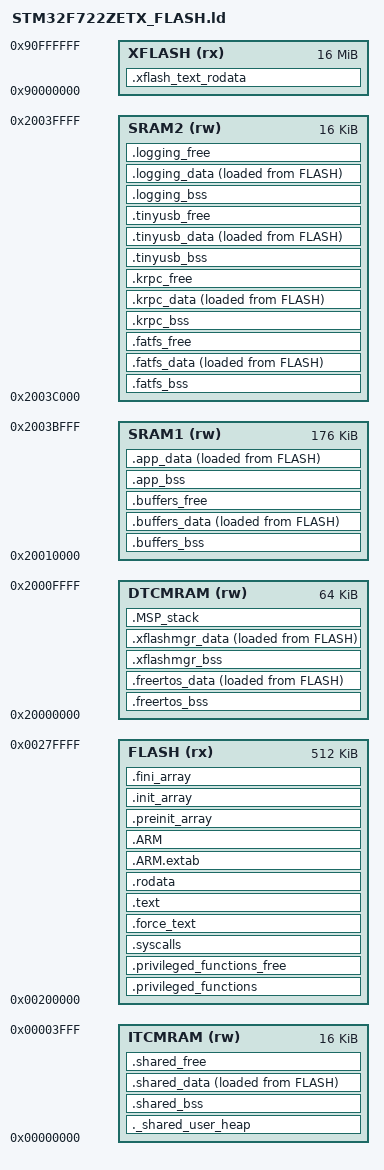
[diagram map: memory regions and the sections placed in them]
/*
******************************************************************************
**
** @file        : LinkerScript.ld
**
** @author      : Auto-generated by STM32CubeIDE
**
** @brief       : Linker script for STM32F722ZETx Device from STM32F7 series
**                      512KBytes FLASH
**                      256KBytes RAM
**
**                Set heap size, stack size and stack location according
**                to application requirements.
**
**                Set memory bank area and size if external memory is used
**
**  Target      : STMicroelectronics STM32
**
**  Distribution: The file is distributed as is, without any warranty
**                of any kind.
**
******************************************************************************
** @attention
**
** Copyright (c) 2023 STMicroelectronics.
** All rights reserved.
**
** This software is licensed under terms that can be found in the LICENSE file
** in the root directory of this software component.
** If no LICENSE file comes with this software, it is provided AS-IS.
**
******************************************************************************
*/

/* Entry Point */
ENTRY(Reset_Handler)

_Min_Heap_Size = 0x1fc; /* required amount of heap */
_Min_Stack_Size = 0x400; /* required amount of stack */

/* Memories definition */
MEMORY
{
	ITCMRAM (rw) : ORIGIN = 0x00000000, LENGTH = 16K
	DTCMRAM (rw) : ORIGIN = 0x20000000, LENGTH = 64K
	SRAM1 (rw) : ORIGIN = 0x20010000, LENGTH = 176K
	SRAM2 (rw) : ORIGIN = 0x2003C000, LENGTH = 16K
	FLASH (rx) : ORIGIN = 0x00200000, LENGTH = 512K
	XFLASH (rx) : ORIGIN = 0x90000000, LENGTH = 16M
}

INCLUDE ../glue/_regions.ld

null_ptr = 0;

/* -------------------------------------------------------------------------- */

/* Sections */
SECTIONS
{
    /* The startup code and FreeRTOS kernel code are placed into privileged
     * flash. */
    .privileged_functions :
    {
        . = ALIGN(4);
        _privileged_functions_text_run_addr = .;
        __FLASH_segment_start__ = .;
        __FLASH_segment_end__ = __FLASH_segment_start__ + LENGTH( FLASH );
        __privileged_functions_start__ = __FLASH_segment_start__;
        
        KEEP(*(.isr_vector)) /* Startup code */
        . = ALIGN(4);
        *(privileged_functions)
        
        . = ALIGN(4);
        _privileged_functions_text_end = .;
    } >FLASH
    
    .privileged_functions_free :
    {
        FILL(0xADDE);
        /* Ensure that un-privileged code is placed after the region reserved
         * for privileged kernel code. */
        /* Note that dot (.) actually refers to the byte offset from the start
         * of the current section (.privileged_functions in this case). As a
         * result, setting dot (.) to a value sets the size of the section. */
        . = __privileged_functions_region_size__ - (_privileged_functions_text_end - _privileged_functions_text_run_addr);
        __privileged_functions_end__ = .;
    } >FLASH
    
    .syscalls :
    {
	    /* Place the FreeRTOS System Calls first in the unprivileged region. */
	    . = ALIGN(4);
	    __syscalls_flash_start__ = .;
	    *(freertos_system_calls)
	    __syscalls_flash_end__ = .;
	    . = ALIGN(4);
    } > FLASH
    
	.force_text :
	{
		. = ALIGN(4);
		
		*(.force_text)
		*(.text.*_IRQHandler)
		./Drivers/*qspi.o(.text* .rodata*) /* */
		./Drivers/*gpio.o(.text* .rodata*) /* */
		
		. = ALIGN(4);
	} > FLASH
	
	.xflash_text_rodata :
	{
		/* Place the FreeRTOS System Calls first in the unprivileged region. */
		. = ALIGN(4);
        __XFLASH_segment_start__ = .;
        __XFLASH_segment_end__ = __XFLASH_segment_start__ + LENGTH( XFLASH );
		*(.xflash_text* .xflash_rodata*)
		./App/*.o(.text* .rodata*) /* */
		./Core/Src/main.o(.text* .rodata*)
		./Core/Src/stm32f7xx_hal_msp.o(.text* .rodata*)
		./Drivers/*.o(.text* .rodata*) /* */
		./lib/Fusion/*.o(.text* .rodata*) /* */
		./lib/FatFs/*.o(.text* .rodata*) /* */ ./glue/FatFs/*.o(.text* .rodata*) /* */
		./lib/krpc-arduino/*.o(.text* .rodata*) /* */
		./lib/tinyusb/*.o(.text* .rodata*) /* */ ./glue/tinyusb/*.o(.text* .rodata*) /* */
		./lib/umm_malloc/*.o(.text* .rodata*) /* */
		. = ALIGN(4);
	} >XFLASH

/* -------------------------------------------------------------------------- */

  /* The program code and other data into "FLASH" Rom type memory */
  .text :
  {
    . = ALIGN(4);
    
    *(.text .text* .glue_7 .glue_7t .eh_frame)
    KEEP (*(.init))
    KEEP (*(.fini))

    . = ALIGN(4);
    _etext = .;
  } >FLASH

  /* Constant data into "FLASH" Rom type memory */
  .rodata :
  {
    . = ALIGN(4);
    *(.rodata .rodata* .force_rodata .force_rodata*)
    . = ALIGN(4);
  } >FLASH

  .ARM.extab (READONLY) : {
    . = ALIGN(4);
    *(.ARM.extab* .gnu.linkonce.armextab.*)
    . = ALIGN(4);
  } >FLASH

  .ARM (READONLY): {
    . = ALIGN(4);
    __exidx_start = .;
    *(.ARM.exidx*)
    __exidx_end = .;
    . = ALIGN(4);
  } >FLASH

  .preinit_array (READONLY) :
  {
    . = ALIGN(4);
    PROVIDE_HIDDEN (__preinit_array_start = .);
    KEEP (*(.preinit_array*))
    PROVIDE_HIDDEN (__preinit_array_end = .);
    . = ALIGN(4);
  } >FLASH

  .init_array (READONLY):
  {
    . = ALIGN(4);
    PROVIDE_HIDDEN (__init_array_start = .);
    KEEP (*(SORT(.init_array.*)))
    KEEP (*(.init_array*))
    PROVIDE_HIDDEN (__init_array_end = .);
    . = ALIGN(4);
  } >FLASH

  .fini_array (READONLY):
  {
    . = ALIGN(4);
    PROVIDE_HIDDEN (__fini_array_start = .);
    KEEP (*(SORT(.fini_array.*)))
    KEEP (*(.fini_array*))
    PROVIDE_HIDDEN (__fini_array_end = .);
    . = ALIGN(4);
  } >FLASH

/* -------------------------------------------------------------------------- */

	.freertos_bss (NOLOAD) :
	{
		. = ALIGN(4);
		_freertos_bss_run_addr = .;
		
		*(.stack)
		./glue/FreeRTOS-Kernel/*.o(.bss*) /* */
		./lib/FreeRTOS-Kernel/*.o(.bss*) /* */
		
		. = ALIGN(4);
		_freertos_bss_end = .;
	} >DTCMRAM

	.freertos_data :
	{
		. = ALIGN(4);
		_freertos_data_run_addr = .;
		
		./glue/FreeRTOS-Kernel/*.o(.data*) /* */
		./lib/FreeRTOS-Kernel/*.o(.data*) /* */
		
		. = ALIGN(4);
		_freertos_data_end = .;
	} >DTCMRAM AT> FLASH
	_freertos_data_load_addr = LOADADDR(.freertos_data);

/* -------------------------------------------------------------------------- */

	.xflashmgr_bss (NOLOAD) :
	{
		. = ALIGN(4);
		_xflashmgr_bss_run_addr = .;
		
		./glue/Avionus_QSPILoader/*.o(.bss*) /* */
		./lib/Avionus_QSPILoader/*.o(.bss*) /* */
		*(.xflashmgr)
		
		. = ALIGN(4);
		_xflashmgr_bss_end = .;
	} >DTCMRAM

	.xflashmgr_data :
	{
		. = ALIGN(4);
		_xflashmgr_data_run_addr = .;
		
		./glue/Avionus_QSPILoader/*.o(.data*) /* */
		./lib/Avionus_QSPILoader/*.o(.data*) /* */
		
		. = ALIGN(4);
		_xflashmgr_data_end = .;
	} >DTCMRAM AT> FLASH
	_xflashmgr_data_load_addr = LOADADDR(.xflashmgr_data);

/* -------------------------------------------------------------------------- */

	.MSP_stack :
	{
		. = ALIGN(8);
		. = . + _Min_Stack_Size;
		. = ALIGN(8);
		_estack = .;
	} >DTCMRAM

/* -------------------------------------------------------------------------- */

	.fatfs_bss (NOLOAD) :
	{
		. = ALIGN(4);
		_fatfs_bss_run_addr = .;
		
		./glue/FatFs/*.o(.bss*) /* */
		./lib/FatFs/*.o(.bss*) /* */
		*(.fatfs)
		
		. = ALIGN(4);
		_fatfs_bss_end = .;
	} >SRAM2

	.fatfs_data :
	{
		. = ALIGN(4);
		_fatfs_data_run_addr = .;
		
		./glue/FatFs/*.o(.data*) /* */
		./lib/FatFs/*.o(.data*) /* */
		
		. = ALIGN(4);
		_fatfs_data_end = .;
	} >SRAM2 AT> FLASH
	_fatfs_data_load_addr = LOADADDR(.fatfs_data);
	
	.fatfs_free (NOLOAD) :
	{
		FILL(0);
		. = __fatfs_data_region_size__ - (_fatfs_data_end - _fatfs_bss_run_addr);
	} >SRAM2

/* -------------------------------------------------------------------------- */

	.krpc_bss (NOLOAD) :
	{
		. = ALIGN(4);
		_krpc_bss_run_addr = .;
		
		./App/modules/krpc_client.o(.bss*)
		./lib/krpc-arduino/*.o(.bss*) /* */
		*(.krpc)
		
		. = ALIGN(4);
		_krpc_bss_end = .;
	} >SRAM2

	.krpc_data :
	{
		. = ALIGN(4);
		_krpc_data_run_addr = .;
		
		./App/modules/krpc_client.o(.data*)
		./lib/krpc-arduino/*.o(.data*) /* */
		
		. = ALIGN(4);
		_krpc_data_end = .;
	} >SRAM2 AT> FLASH
	_krpc_data_load_addr = LOADADDR(.krpc_data);
	
	.krpc_free (NOLOAD) :
	{
		FILL(0);
		. = __krpc_data_region_size__ - (_krpc_data_end - _krpc_bss_run_addr);
	} >SRAM2

/* -------------------------------------------------------------------------- */

	.tinyusb_bss (NOLOAD) :
	{
		. = ALIGN(4);
		_tinyusb_bss_run_addr = .;
		
		./lib/tinyusb/*.o(.bss*) /* */
		./glue/tinyusb/*.o(.bss*) /* */
		./App/hw/usb.o(.bss*)
		*(.tinyusb)
		
		. = ALIGN(4);
		_tinyusb_bss_end = .;
	} >SRAM2

	.tinyusb_data :
	{
		. = ALIGN(4);
		_tinyusb_data_run_addr = .;
		
		./lib/tinyusb/*.o(.data*) /* */
		./glue/tinyusb/*.o(.data*) /* */
		./App/hw/usb.o(.data*)
		
		. = ALIGN(4);
		_tinyusb_data_end = .;
	} >SRAM2 AT> FLASH
	_tinyusb_data_load_addr = LOADADDR(.tinyusb_data);
	
	.tinyusb_free (NOLOAD) :
	{
		FILL(0);
		. = __tinyusb_data_region_size__ - (_tinyusb_data_end - _tinyusb_bss_run_addr);
	} >SRAM2

/* -------------------------------------------------------------------------- */

	.logging_bss (NOLOAD) :
	{
		. = ALIGN(4);
		_logging_bss_run_addr = .;
		
		./App/modules/logging.o(.bss*)
		*(.logging)
		
		. = ALIGN(4);
		_logging_bss_end = .;
	} >SRAM2

	.logging_data :
	{
		. = ALIGN(4);
		_logging_data_run_addr = .;
		
		./App/modules/logging.o(.data*)
		
		. = ALIGN(4);
		_logging_data_end = .;
	} >SRAM2 AT> FLASH
	_logging_data_load_addr = LOADADDR(.logging_data);
	
	.logging_free (NOLOAD) :
	{
		FILL(0);
		. = __logging_data_region_size__ - (_logging_data_end - _logging_bss_run_addr);
	} >SRAM2

/* -------------------------------------------------------------------------- */

	.buffers_bss (NOLOAD) :
	{
		. = ALIGN(4);
		_buffers_bss_run_addr = .;
		
		*(.buffers)
		
		. = ALIGN(4);
		_buffers_bss_end = .;
	} >SRAM1

	.buffers_data :
	{
		. = ALIGN(4);
		_buffers_data_run_addr = .;
		
		*(.buffers_data)
		
		. = ALIGN(4);
		_buffers_data_end = .;
	} >SRAM1 AT> FLASH
	_buffers_data_load_addr = LOADADDR(.buffers_data);
	
	.buffers_free (NOLOAD) :
	{
		FILL(0);
		. = __buffers_data_region_size__ - (_buffers_data_end - _buffers_bss_run_addr);
	} >SRAM1



	.app_bss (NOLOAD) :
	{
		. = ALIGN(4);
		_app_bss_run_addr = .;
		
		./App/*.o(.bss*) /* */
		*(.app)
		
		. = ALIGN(4);
		_app_bss_end = .;
	} >SRAM1

	.app_data :
	{
		. = ALIGN(4);
		_app_data_run_addr = .;
		
		./App/*.o(.data*) /* */
		
		. = ALIGN(4);
		_app_data_end = .;
	} >SRAM1 AT> FLASH
	_app_data_load_addr = LOADADDR(.app_data);

/* -------------------------------------------------------------------------- */

	._shared_user_heap :
	{
		_shared_bss_run_addr = .;
		__SHARED_SRAM_segment_start__ = .;
		. = 1;
		. = ALIGN(4);
		PROVIDE ( end = . );
		PROVIDE ( _end = . );
		. = . + _Min_Heap_Size;
		. = ALIGN(4);
		_eheap = .;
	} >ITCMRAM

	.shared_bss (NOLOAD) :
	{
		. = ALIGN(4);
		
		./Core/*.o(.bss*) /* */
		./Drivers/*.o(.bss*) /* */
	    *(.bss)
	    *(.bss*)
	    *(COMMON)
	    *(.shared)
		
		. = ALIGN(4);
		_shared_bss_end = .;
	} >ITCMRAM

	.shared_data :
	{
		. = ALIGN(4);
		_shared_data_run_addr = .;
		
		./Core/*.o(.data*) /* */
		./Drivers/*.o(.data*) /* */
	    *(.data)           /* .data sections */
    	*(.data*)          /* .data* sections */
    	/*    *(.RamFunc)        /* .RamFunc sections */
		/*    *(.RamFunc*)       /* .RamFunc* sections */
		
		. = ALIGN(4);
		_shared_data_end = .;
	} >ITCMRAM AT> FLASH
	_shared_data_load_addr = LOADADDR(.shared_data);
	
	.shared_free (NOLOAD) :
	{
		FILL(0);
		. = __shared_region_size__ - (_shared_data_end - _shared_bss_run_addr);
		__SHARED_SRAM_segment_end__ = .;
	} >ITCMRAM

/* -------------------------------------------------------------------------- */

  /* Remove information from the compiler libraries */
  /DISCARD/ :
  {
    libc.a ( * )
    libm.a ( * )
    libgcc.a ( * )
  }

  .ARM.attributes 0 : { *(.ARM.attributes) }
}
